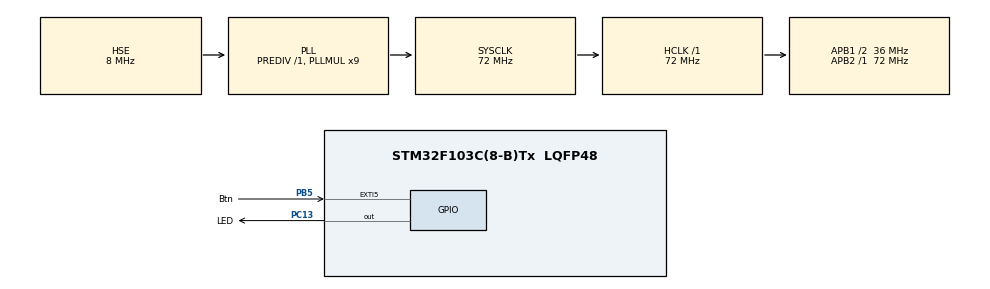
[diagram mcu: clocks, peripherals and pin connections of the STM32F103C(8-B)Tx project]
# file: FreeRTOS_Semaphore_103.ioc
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FREERTOS.BinarySemaphores01=Binary_Sem,Dynamic,NULL
FREERTOS.Tasks01=Task_1,0,128,StartTask_1,Default,NULL,Dynamic,NULL,NULL;Task_2,0,128,StartTask_2,Default,NULL,Dynamic,NULL,NULL
FREERTOS.configLIBRARY_LOWEST_INTERRUPT_PRIORITY=3
FREERTOS.configLIBRARY_MAX_SYSCALL_INTERRUPT_PRIORITY=2
FREERTOS.configUSE_NEWLIB_REENTRANT=1
FREERTOS.configUSE_TIMERS=0
Mcu.Family=STM32F1
Mcu.Name=STM32F103C(8-B)Tx
Mcu.Package=LQFP48
NVIC.EXTI9_5_IRQn=true\:2\:0\:false\:false\:true\:true\:true\:true\:true
NVIC.PriorityGroup=NVIC_PRIORITYGROUP_4
NVIC.TIM4_IRQn=true\:0\:0\:true\:false\:true\:false\:false\:true\:true
NVIC.TimeBase=TIM4_IRQn
NVIC.TimeBaseIP=TIM4
PA13.Mode=Serial_Wire
PA13.Signal=SYS_JTMS-SWDIO
PA14.Mode=Serial_Wire
PA14.Signal=SYS_JTCK-SWCLK
PB5.GPIO_Label=Btn
PB5.GPIO_ModeDefaultEXTI=GPIO_MODE_IT_FALLING
PB5.GPIO_PuPd=GPIO_PULLUP
PB5.Signal=GPXTI5
PC13-TAMPER-RTC.GPIO_Label=LED
PC13-TAMPER-RTC.PinState=GPIO_PIN_SET
PC13-TAMPER-RTC.Signal=GPIO_Output
PD0-OSC_IN.Mode=HSE-External-Oscillator
PD0-OSC_IN.Signal=RCC_OSC_IN
PD1-OSC_OUT.Mode=HSE-External-Oscillator
PD1-OSC_OUT.Signal=RCC_OSC_OUT
ProjectManager.HeapSize=0x200
ProjectManager.StackSize=0x400
ProjectManager.TargetToolchain=STM32CubeIDE
RCC.AHBFreq_Value=72000000
RCC.APB1CLKDivider=RCC_HCLK_DIV2
RCC.APB1Freq_Value=36000000
RCC.APB1TimFreq_Value=72000000
RCC.APB2Freq_Value=72000000
RCC.APB2TimFreq_Value=72000000
RCC.HCLKFreq_Value=72000000
RCC.PLLMUL=RCC_PLL_MUL9
RCC.PLLSourceVirtual=RCC_PLLSOURCE_HSE
RCC.SYSCLKFreq_VALUE=72000000
RCC.SYSCLKSource=RCC_SYSCLKSOURCE_PLLCLK
RCC.USBFreq_Value=72000000
VP_FREERTOS_VS_CMSIS_V1.Mode=CMSIS_V1
VP_SYS_VS_tim4.Mode=TIM4
board=custom

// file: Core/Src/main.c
/* USER CODE BEGIN Header */
/**
  ******************************************************************************
  * @file           : main.c
  * @brief          : Main program body
  ******************************************************************************
  * @attention
  *
  * Copyright (c) 2023 STMicroelectronics.
  * All rights reserved.
  *
  * This software is licensed under terms that can be found in the LICENSE file
  * in the root directory of this software component.
  * If no LICENSE file comes with this software, it is provided AS-IS.
  *
  ******************************************************************************
  */
/* USER CODE END Header */
#include "main.h"
#include "cmsis_os.h"

osThreadId Task_1Handle;
osThreadId Task_2Handle;
osSemaphoreId Binary_SemHandle;

void SystemClock_Config(void);
static void MX_GPIO_Init(void);
void StartTask_1(void const * argument);
void StartTask_2(void const * argument);

int main(void)
{

  /* MCU Configuration--------------------------------------------------------*/

  /* Reset of all peripherals, Initializes the Flash interface and the Systick. */
  HAL_Init();

  /* Configure the system clock */
  SystemClock_Config();

  /* Initialize all configured peripherals */
  MX_GPIO_Init();

  /* Create the semaphores(s) */
  /* definition and creation of Binary_Sem */
  osSemaphoreDef(Binary_Sem);
  Binary_SemHandle = osSemaphoreCreate(osSemaphore(Binary_Sem), 1);

  /* Create the thread(s) */
  /* definition and creation of Task_1 */
  osThreadDef(Task_1, StartTask_1, osPriorityNormal, 0, 128);
  Task_1Handle = osThreadCreate(osThread(Task_1), NULL);

  /* definition and creation of Task_2 */
  osThreadDef(Task_2, StartTask_2, osPriorityNormal, 0, 128);
  Task_2Handle = osThreadCreate(osThread(Task_2), NULL);

  /* Start scheduler */
  osKernelStart();

  /* We should never get here as control is now taken by the scheduler */
  /* Infinite loop */
  while (1)
  {

  }
}

void SystemClock_Config(void)
{
  RCC_OscInitTypeDef RCC_OscInitStruct = {0};
  RCC_ClkInitTypeDef RCC_ClkInitStruct = {0};

  /** Initializes the RCC Oscillators according to the specified parameters
  * in the RCC_OscInitTypeDef structure.
  */
  RCC_OscInitStruct.OscillatorType = RCC_OSCILLATORTYPE_HSE;
  RCC_OscInitStruct.HSEState = RCC_HSE_ON;
  RCC_OscInitStruct.HSEPredivValue = RCC_HSE_PREDIV_DIV1;
  RCC_OscInitStruct.HSIState = RCC_HSI_ON;
  RCC_OscInitStruct.PLL.PLLState = RCC_PLL_ON;
  RCC_OscInitStruct.PLL.PLLSource = RCC_PLLSOURCE_HSE;
  RCC_OscInitStruct.PLL.PLLMUL = RCC_PLL_MUL9;
  if (HAL_RCC_OscConfig(&RCC_OscInitStruct) != HAL_OK)
  {
    Error_Handler();
  }

  /** Initializes the CPU, AHB and APB buses clocks
  */
  RCC_ClkInitStruct.ClockType = RCC_CLOCKTYPE_HCLK|RCC_CLOCKTYPE_SYSCLK
                              |RCC_CLOCKTYPE_PCLK1|RCC_CLOCKTYPE_PCLK2;
  RCC_ClkInitStruct.SYSCLKSource = RCC_SYSCLKSOURCE_PLLCLK;
  RCC_ClkInitStruct.AHBCLKDivider = RCC_SYSCLK_DIV1;
  RCC_ClkInitStruct.APB1CLKDivider = RCC_HCLK_DIV2;
  RCC_ClkInitStruct.APB2CLKDivider = RCC_HCLK_DIV1;

  if (HAL_RCC_ClockConfig(&RCC_ClkInitStruct, FLASH_LATENCY_2) != HAL_OK)
  {
    Error_Handler();
  }
}

static void MX_GPIO_Init(void)
{
  GPIO_InitTypeDef GPIO_InitStruct = {0};

  /* GPIO Ports Clock Enable */
  __HAL_RCC_GPIOC_CLK_ENABLE();
  __HAL_RCC_GPIOD_CLK_ENABLE();
  __HAL_RCC_GPIOA_CLK_ENABLE();
  __HAL_RCC_GPIOB_CLK_ENABLE();

  /*Configure GPIO pin Output Level */
  HAL_GPIO_WritePin(LED_GPIO_Port, LED_Pin, GPIO_PIN_SET);

  /*Configure GPIO pin : LED_Pin */
  GPIO_InitStruct.Pin = LED_Pin;
  GPIO_InitStruct.Mode = GPIO_MODE_OUTPUT_PP;
  GPIO_InitStruct.Pull = GPIO_NOPULL;
  GPIO_InitStruct.Speed = GPIO_SPEED_FREQ_LOW;
  HAL_GPIO_Init(LED_GPIO_Port, &GPIO_InitStruct);

  /*Configure GPIO pin : Btn_Pin */
  GPIO_InitStruct.Pin = Btn_Pin;
  GPIO_InitStruct.Mode = GPIO_MODE_IT_FALLING;
  GPIO_InitStruct.Pull = GPIO_PULLUP;
  HAL_GPIO_Init(Btn_GPIO_Port, &GPIO_InitStruct);

  /* EXTI interrupt init*/
  HAL_NVIC_SetPriority(EXTI9_5_IRQn, 2, 0);
  HAL_NVIC_EnableIRQ(EXTI9_5_IRQn);

}

/* USER CODE BEGIN 4 */
void HAL_GPIO_EXTI_Callback(uint16_t GPIO_Pin)
{
	if(Btn_Pin == GPIO_Pin) // Если нажали на кнопку
	{
		osSemaphoreRelease(Binary_SemHandle); // дали отмашку на включение светодиода
	}
}
/* USER CODE END 4 */

void StartTask_1(void const * argument)
{
  /* USER CODE BEGIN 5 */
  /* Infinite loop */
  for(;;)
  {
	HAL_GPIO_WritePin(LED_GPIO_Port, LED_Pin, GPIO_PIN_RESET); // 'On' если Semaphor Release!
    osSemaphoreWait(Binary_SemHandle, osWaitForever);
	//osDelay(1000);
  }
  /* USER CODE END 5 */
}

void StartTask_2(void const * argument)
{
  /* USER CODE BEGIN StartTask_2 */
  /* Infinite loop */
  for(;;)
  {
		HAL_GPIO_WritePin(LED_GPIO_Port, LED_Pin, GPIO_PIN_SET); // 'Off'
	    osDelay(2000);
  }
  /* USER CODE END StartTask_2 */
}

void HAL_TIM_PeriodElapsedCallback(TIM_HandleTypeDef *htim)
{
  if (htim->Instance == TIM4) {
    HAL_IncTick();
  }
}

void Error_Handler(void)
{
  __disable_irq();
  while (1)
  {
  }
}
